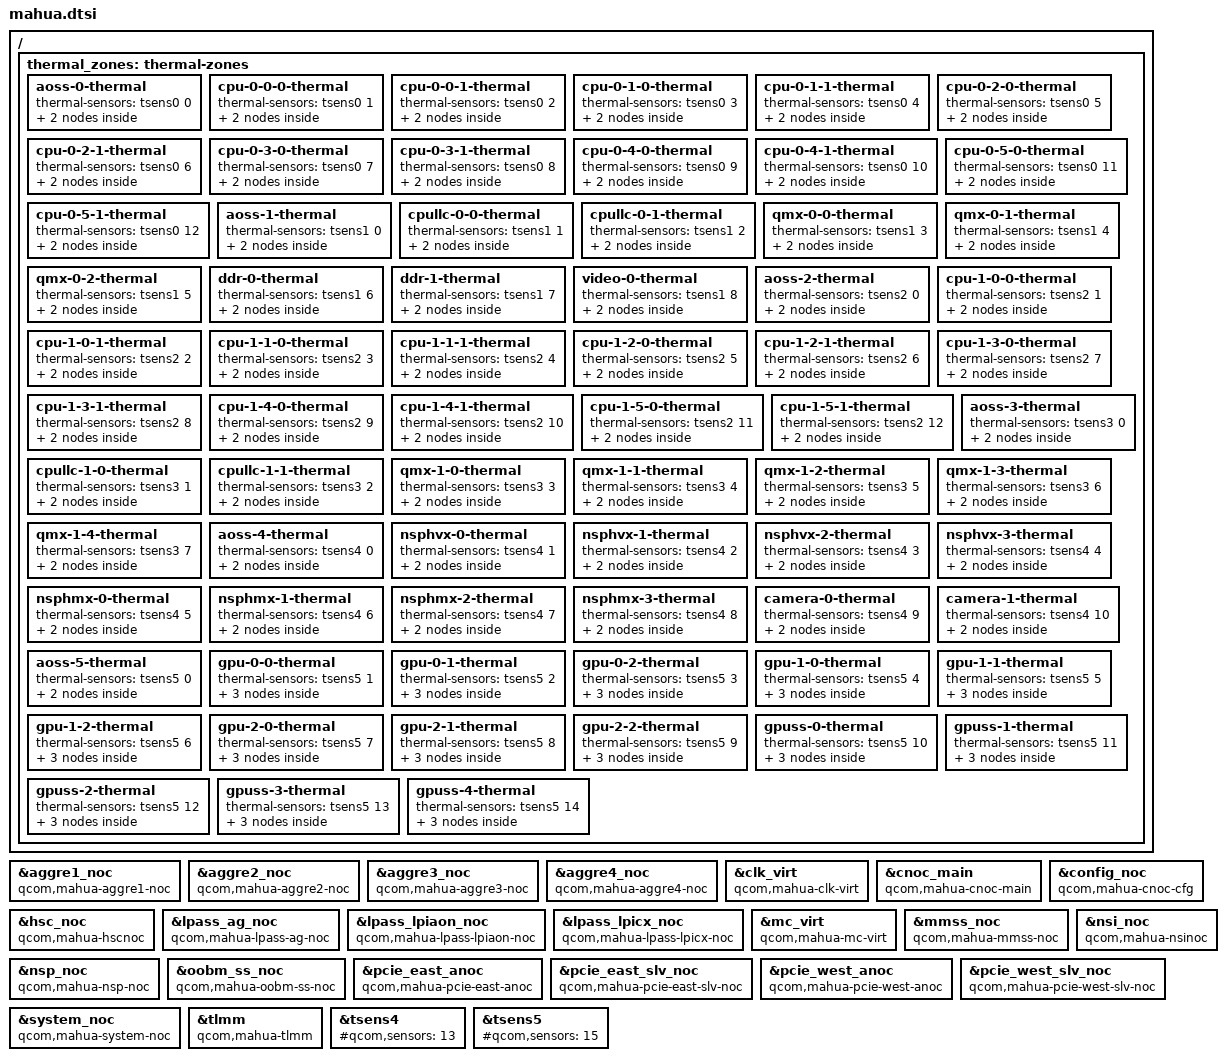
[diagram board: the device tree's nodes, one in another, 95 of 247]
// SPDX-License-Identifier: BSD-3-Clause
/*
 * Copyright (c) Qualcomm Technologies, Inc. and/or its subsidiaries.
 */

/* Mahua is heavily based on Glymur, with some meaningful differences */
#include "glymur.dtsi"

/delete-node/ &cluster2_pd;
/delete-node/ &cpu_map_cluster2;
/delete-node/ &cpu12;
/delete-node/ &cpu13;
/delete-node/ &cpu14;
/delete-node/ &cpu15;
/delete-node/ &cpu16;
/delete-node/ &cpu17;
/delete-node/ &cpu_pd12;
/delete-node/ &cpu_pd13;
/delete-node/ &cpu_pd14;
/delete-node/ &cpu_pd15;
/delete-node/ &cpu_pd16;
/delete-node/ &cpu_pd17;
/delete-node/ &thermal_zones;
/delete-node/ &tsens6;
/delete-node/ &tsens7;

&aggre1_noc {
	compatible = "qcom,mahua-aggre1-noc", "qcom,glymur-aggre1-noc";
};

&aggre2_noc {
	compatible = "qcom,mahua-aggre2-noc", "qcom,glymur-aggre2-noc";
};

&aggre3_noc {
	compatible = "qcom,mahua-aggre3-noc", "qcom,glymur-aggre3-noc";
};

&aggre4_noc {
	compatible = "qcom,mahua-aggre4-noc", "qcom,glymur-aggre4-noc";
};

&clk_virt {
	compatible = "qcom,mahua-clk-virt", "qcom,glymur-clk-virt";
};

&cnoc_main {
	compatible = "qcom,mahua-cnoc-main", "qcom,glymur-cnoc-main";
};

&config_noc {
	compatible = "qcom,mahua-cnoc-cfg";
};

&hsc_noc {
	compatible = "qcom,mahua-hscnoc";
};

&lpass_ag_noc {
	compatible = "qcom,mahua-lpass-ag-noc", "qcom,glymur-lpass-ag-noc";
};

&lpass_lpiaon_noc {
	compatible = "qcom,mahua-lpass-lpiaon-noc", "qcom,glymur-lpass-lpiaon-noc";
};

&lpass_lpicx_noc {
	compatible = "qcom,mahua-lpass-lpicx-noc", "qcom,glymur-lpass-lpicx-noc";
};

&mc_virt {
	compatible = "qcom,mahua-mc-virt";
};

&mmss_noc {
	compatible = "qcom,mahua-mmss-noc", "qcom,glymur-mmss-noc";
};

&nsi_noc {
	compatible = "qcom,mahua-nsinoc", "qcom,glymur-nsinoc";
};

&nsp_noc {
	compatible = "qcom,mahua-nsp-noc", "qcom,glymur-nsp-noc";
};

&oobm_ss_noc {
	compatible = "qcom,mahua-oobm-ss-noc", "qcom,glymur-oobm-ss-noc";
};

&pcie_east_anoc {
	compatible = "qcom,mahua-pcie-east-anoc", "qcom,glymur-pcie-east-anoc";
};

&pcie_east_slv_noc {
	compatible = "qcom,mahua-pcie-east-slv-noc", "qcom,glymur-pcie-east-slv-noc";
};

&pcie_west_anoc {
	compatible = "qcom,mahua-pcie-west-anoc";
	clocks = <&gcc GCC_AGGRE_NOC_PCIE_3B_WEST_SF_AXI_CLK>,
		 <&gcc GCC_AGGRE_NOC_PCIE_4_WEST_SF_AXI_CLK>,
		 <&gcc GCC_AGGRE_NOC_PCIE_6_WEST_SF_AXI_CLK>;
};

&pcie_west_slv_noc {
	compatible = "qcom,mahua-pcie-west-slv-noc";
};

&system_noc {
	compatible = "qcom,mahua-system-noc", "qcom,glymur-system-noc";
};

&tlmm {
	compatible = "qcom,mahua-tlmm";
};

&tsens4 {
	#qcom,sensors = <13>;
};

&tsens5 {
	#qcom,sensors = <15>;
};

/ {
	thermal_zones: thermal-zones {
		aoss-0-thermal {
			thermal-sensors = <&tsens0 0>;

			trips {
				aoss-0-critical {
					temperature = <115000>;
					hysteresis = <1000>;
					type = "critical";
				};
			};
		};

		cpu-0-0-0-thermal {
			thermal-sensors = <&tsens0 1>;

			trips {
				cpu-0-0-0-critical {
					temperature = <115000>;
					hysteresis = <1000>;
					type = "critical";
				};
			};
		};

		cpu-0-0-1-thermal {
			thermal-sensors = <&tsens0 2>;

			trips {
				cpu-0-0-1-critical {
					temperature = <115000>;
					hysteresis = <1000>;
					type = "critical";
				};
			};
		};

		cpu-0-1-0-thermal {
			thermal-sensors = <&tsens0 3>;

			trips {
				cpu-0-1-0-critical {
					temperature = <115000>;
					hysteresis = <1000>;
					type = "critical";
				};
			};
		};

		cpu-0-1-1-thermal {
			thermal-sensors = <&tsens0 4>;

			trips {
				cpu-0-1-1-critical {
					temperature = <115000>;
					hysteresis = <1000>;
					type = "critical";
				};
			};
		};

		cpu-0-2-0-thermal {
			thermal-sensors = <&tsens0 5>;

			trips {
				cpu-0-2-0-critical {
					temperature = <115000>;
					hysteresis = <1000>;
					type = "critical";
				};
			};
		};

		cpu-0-2-1-thermal {
			thermal-sensors = <&tsens0 6>;

			trips {
				cpu-0-2-1-critical {
					temperature = <115000>;
					hysteresis = <1000>;
					type = "critical";
				};
			};
		};

		cpu-0-3-0-thermal {
			thermal-sensors = <&tsens0 7>;

			trips {
				cpu-0-3-0-critical {
					temperature = <115000>;
					hysteresis = <1000>;
					type = "critical";
				};
			};
		};

		cpu-0-3-1-thermal {
			thermal-sensors = <&tsens0 8>;

			trips {
				cpu-0-3-1-critical {
					temperature = <115000>;
					hysteresis = <1000>;
					type = "critical";
				};
			};
		};

		cpu-0-4-0-thermal {
			thermal-sensors = <&tsens0 9>;

			trips {
				cpu-0-4-0-critical {
					temperature = <115000>;
					hysteresis = <1000>;
					type = "critical";
				};
			};
		};

		cpu-0-4-1-thermal {
			thermal-sensors = <&tsens0 10>;

			trips {
				cpu-0-4-1-critical {
					temperature = <115000>;
					hysteresis = <1000>;
					type = "critical";
				};
			};
		};

		cpu-0-5-0-thermal {
			thermal-sensors = <&tsens0 11>;

			trips {
				cpu-0-5-0-critical {
					temperature = <115000>;
					hysteresis = <1000>;
					type = "critical";
				};
			};
		};

		cpu-0-5-1-thermal {
			thermal-sensors = <&tsens0 12>;

			trips {
				cpu-0-5-1-critical {
					temperature = <115000>;
					hysteresis = <1000>;
					type = "critical";
				};
			};
		};

		aoss-1-thermal {
			thermal-sensors = <&tsens1 0>;

			trips {
				aoss-1-critical {
					temperature = <115000>;
					hysteresis = <1000>;
					type = "critical";
				};
			};
		};

		cpullc-0-0-thermal {
			thermal-sensors = <&tsens1 1>;

			trips {
				cpullc-0-0-critical {
					temperature = <115000>;
					hysteresis = <1000>;
					type = "critical";
				};
			};
		};

		cpullc-0-1-thermal {
			thermal-sensors = <&tsens1 2>;

			trips {
				cpullc-0-1-critical {
					temperature = <115000>;
					hysteresis = <1000>;
					type = "critical";
				};
			};
		};

		qmx-0-0-thermal {
			thermal-sensors = <&tsens1 3>;

			trips {
				qmx-0-0-critical {
					temperature = <115000>;
					hysteresis = <1000>;
					type = "critical";
				};
			};
		};

		qmx-0-1-thermal {
			thermal-sensors = <&tsens1 4>;

			trips {
				qmx-0-1-critical {
					temperature = <115000>;
					hysteresis = <1000>;
					type = "critical";
				};
			};
		};

		qmx-0-2-thermal {
			thermal-sensors = <&tsens1 5>;

			trips {
				qmx-0-2-critical {
					temperature = <115000>;
					hysteresis = <1000>;
					type = "critical";
				};
			};
		};

		ddr-0-thermal {
			thermal-sensors = <&tsens1 6>;

			trips {
				ddr-0-critical {
					temperature = <115000>;
					hysteresis = <1000>;
					type = "critical";
				};
			};
		};

		ddr-1-thermal {
			thermal-sensors = <&tsens1 7>;

			trips {
				ddr-1-critical {
					temperature = <115000>;
					hysteresis = <1000>;
					type = "critical";
				};
			};
		};

		video-0-thermal {
			thermal-sensors = <&tsens1 8>;

			trips {
				video-0-critical {
					temperature = <115000>;
					hysteresis = <1000>;
					type = "critical";
				};
			};
		};

		aoss-2-thermal {
			thermal-sensors = <&tsens2 0>;

			trips {
				aoss-2-critical {
					temperature = <115000>;
					hysteresis = <1000>;
					type = "critical";
				};
			};
		};

		cpu-1-0-0-thermal {
			thermal-sensors = <&tsens2 1>;

			trips {
				cpu-1-0-0-critical {
					temperature = <115000>;
					hysteresis = <1000>;
					type = "critical";
				};
			};
		};

		cpu-1-0-1-thermal {
			thermal-sensors = <&tsens2 2>;

			trips {
				cpu-1-0-1-critical {
					temperature = <115000>;
					hysteresis = <1000>;
					type = "critical";
				};
			};
		};

		cpu-1-1-0-thermal {
			thermal-sensors = <&tsens2 3>;

			trips {
				cpu-1-1-0-critical {
					temperature = <115000>;
					hysteresis = <1000>;
					type = "critical";
				};
			};
		};

		cpu-1-1-1-thermal {
			thermal-sensors = <&tsens2 4>;

			trips {
				cpu-1-1-1-critical {
					temperature = <115000>;
					hysteresis = <1000>;
					type = "critical";
				};
			};
		};

		cpu-1-2-0-thermal {
			thermal-sensors = <&tsens2 5>;

			trips {
				cpu-1-2-0-critical {
					temperature = <115000>;
					hysteresis = <1000>;
					type = "critical";
				};
			};
		};

		cpu-1-2-1-thermal {
			thermal-sensors = <&tsens2 6>;

			trips {
				cpu-1-2-1-critical {
					temperature = <115000>;
					hysteresis = <1000>;
					type = "critical";
				};
			};
		};

		cpu-1-3-0-thermal {
			thermal-sensors = <&tsens2 7>;

			trips {
				cpu-1-3-0-critical {
					temperature = <115000>;
					hysteresis = <1000>;
					type = "critical";
				};
			};
		};

		cpu-1-3-1-thermal {
			thermal-sensors = <&tsens2 8>;

			trips {
				cpu-1-3-1-critical {
					temperature = <115000>;
					hysteresis = <1000>;
					type = "critical";
				};
			};
		};

		cpu-1-4-0-thermal {
			thermal-sensors = <&tsens2 9>;

			trips {
				cpu-1-4-0-critical {
					temperature = <115000>;
					hysteresis = <1000>;
					type = "critical";
				};
			};
		};

		cpu-1-4-1-thermal {
			thermal-sensors = <&tsens2 10>;

			trips {
				cpu-1-4-1-critical {
					temperature = <115000>;
					hysteresis = <1000>;
					type = "critical";
				};
			};
		};

		cpu-1-5-0-thermal {
			thermal-sensors = <&tsens2 11>;

			trips {
				cpu-1-5-0-critical {
					temperature = <115000>;
					hysteresis = <1000>;
					type = "critical";
				};
			};
		};

		cpu-1-5-1-thermal {
			thermal-sensors = <&tsens2 12>;

			trips {
				cpu-1-5-1-critical {
					temperature = <115000>;
					hysteresis = <1000>;
					type = "critical";
				};
			};
		};

		aoss-3-thermal {
			thermal-sensors = <&tsens3 0>;

			trips {
				aoss-3-critical {
					temperature = <115000>;
					hysteresis = <1000>;
					type = "critical";
				};
			};
		};

		cpullc-1-0-thermal {
			thermal-sensors = <&tsens3 1>;

			trips {
				cpullc-1-0-critical {
					temperature = <115000>;
					hysteresis = <1000>;
					type = "critical";
				};
			};
		};

		cpullc-1-1-thermal {
			thermal-sensors = <&tsens3 2>;

			trips {
				cpullc-1-1-critical {
					temperature = <115000>;
					hysteresis = <1000>;
					type = "critical";
				};
			};
		};

		qmx-1-0-thermal {
			thermal-sensors = <&tsens3 3>;

			trips {
				qmx-1-0-critical {
					temperature = <115000>;
					hysteresis = <1000>;
					type = "critical";
				};
			};
		};

		qmx-1-1-thermal {
			thermal-sensors = <&tsens3 4>;

			trips {
				qmx-1-1-critical {
					temperature = <115000>;
					hysteresis = <1000>;
					type = "critical";
				};
			};
		};

		qmx-1-2-thermal {
			thermal-sensors = <&tsens3 5>;

			trips {
				qmx-1-2-critical {
					temperature = <115000>;
					hysteresis = <1000>;
					type = "critical";
				};
			};
		};

		qmx-1-3-thermal {
			thermal-sensors = <&tsens3 6>;

			trips {
				qmx-1-3-critical {
					temperature = <115000>;
					hysteresis = <1000>;
					type = "critical";
				};
			};
		};

		qmx-1-4-thermal {
			thermal-sensors = <&tsens3 7>;

			trips {
				qmx-1-4-critical {
					temperature = <115000>;
					hysteresis = <1000>;
					type = "critical";
				};
			};
		};

		aoss-4-thermal {
			thermal-sensors = <&tsens4 0>;

			trips {
				aoss-4-critical {
					temperature = <115000>;
					hysteresis = <1000>;
					type = "critical";
				};
			};
		};

		nsphvx-0-thermal {
			thermal-sensors = <&tsens4 1>;

			trips {
				nsphvx-0-critical {
					temperature = <115000>;
					hysteresis = <1000>;
					type = "critical";
				};
			};
		};

		nsphvx-1-thermal {
			thermal-sensors = <&tsens4 2>;

			trips {
				nsphvx-1-critical {
					temperature = <115000>;
					hysteresis = <1000>;
					type = "critical";
				};
			};
		};

		nsphvx-2-thermal {
			thermal-sensors = <&tsens4 3>;

			trips {
				nsphvx-2-critical {
					temperature = <115000>;
					hysteresis = <1000>;
					type = "critical";
				};
			};
		};

		nsphvx-3-thermal {
			thermal-sensors = <&tsens4 4>;

			trips {
				nsphvx-3-critical {
					temperature = <115000>;
					hysteresis = <1000>;
					type = "critical";
				};
			};
		};

		nsphmx-0-thermal {
			thermal-sensors = <&tsens4 5>;

			trips {
				nsphmx-0-critical {
					temperature = <115000>;
					hysteresis = <1000>;
					type = "critical";
				};
			};
		};

		nsphmx-1-thermal {
			thermal-sensors = <&tsens4 6>;

			trips {
				nsphmx-1-critical {
					temperature = <115000>;
					hysteresis = <1000>;
					type = "critical";
				};
			};
		};

		nsphmx-2-thermal {
			thermal-sensors = <&tsens4 7>;

			trips {
				nsphmx-2-critical {
					temperature = <115000>;
					hysteresis = <1000>;
					type = "critical";
				};
			};
		};

		nsphmx-3-thermal {
			thermal-sensors = <&tsens4 8>;

			trips {
				nsphmx-3-critical {
					temperature = <115000>;
					hysteresis = <1000>;
					type = "critical";
				};
			};
		};

		camera-0-thermal {
			thermal-sensors = <&tsens4 9>;

			trips {
				camera-0-critical {
					temperature = <115000>;
					hysteresis = <1000>;
					type = "critical";
				};
			};
		};

		camera-1-thermal {
			thermal-sensors = <&tsens4 10>;

			trips {
				camera-1-critical {
					temperature = <115000>;
					hysteresis = <1000>;
					type = "critical";
				};
			};
		};

		aoss-5-thermal {
			thermal-sensors = <&tsens5 0>;

			trips {
				aoss-5-critical {
					temperature = <115000>;
					hysteresis = <1000>;
					type = "critical";
				};
			};
		};

		gpu-0-0-thermal {
			thermal-sensors = <&tsens5 1>;

			trips {
				trip-point0 {
					temperature = <90000>;
					hysteresis = <5000>;
					type = "hot";
				};

				gpu-0-0-critical {
					temperature = <115000>;
					hysteresis = <1000>;
					type = "critical";
				};
			};
		};

		gpu-0-1-thermal {
			thermal-sensors = <&tsens5 2>;

			trips {
				trip-point0 {
					temperature = <90000>;
					hysteresis = <5000>;
					type = "hot";
				};

				gpu-0-1-critical {
					temperature = <115000>;
					hysteresis = <1000>;
					type = "critical";
				};
			};
		};

		gpu-0-2-thermal {
			thermal-sensors = <&tsens5 3>;

			trips {
				trip-point0 {
					temperature = <90000>;
					hysteresis = <5000>;
					type = "hot";
				};

				gpu-0-2-critical {
					temperature = <115000>;
					hysteresis = <1000>;
					type = "critical";
				};
			};
		};

		gpu-1-0-thermal {
			thermal-sensors = <&tsens5 4>;

			trips {
				trip-point0 {
					temperature = <90000>;
					hysteresis = <5000>;
					type = "hot";
				};

				gpu-1-0-critical {
					temperature = <115000>;
					hysteresis = <1000>;
					type = "critical";
				};
			};
		};

		gpu-1-1-thermal {
			thermal-sensors = <&tsens5 5>;

			trips {
				trip-point0 {
					temperature = <90000>;
					hysteresis = <5000>;
					type = "hot";
				};

				gpu-1-1-critical {
					temperature = <115000>;
					hysteresis = <1000>;
					type = "critical";
				};
			};
		};

		gpu-1-2-thermal {
			thermal-sensors = <&tsens5 6>;

			trips {
				trip-point0 {
					temperature = <90000>;
					hysteresis = <5000>;
					type = "hot";
				};

				gpu-1-2-critical {
					temperature = <115000>;
					hysteresis = <1000>;
					type = "critical";
				};
			};
		};

		gpu-2-0-thermal {
			thermal-sensors = <&tsens5 7>;

			trips {
				trip-point0 {
					temperature = <90000>;
					hysteresis = <5000>;
					type = "hot";
				};

				gpu-2-0-critical {
					temperature = <115000>;
					hysteresis = <1000>;
					type = "critical";
				};
			};
		};

		gpu-2-1-thermal {
			thermal-sensors = <&tsens5 8>;

			trips {
				trip-point0 {
					temperature = <90000>;
					hysteresis = <5000>;
					type = "hot";
				};

				gpu-2-1-critical {
					temperature = <115000>;
					hysteresis = <1000>;
					type = "critical";
				};
			};
		};

		gpu-2-2-thermal {
			thermal-sensors = <&tsens5 9>;

			trips {
				trip-point0 {
					temperature = <90000>;
					hysteresis = <5000>;
					type = "hot";
				};

				gpu-2-2-critical {
					temperature = <115000>;
					hysteresis = <1000>;
					type = "critical";
				};
			};
		};

		gpuss-0-thermal {
			thermal-sensors = <&tsens5 10>;

			trips {
				trip-point0 {
					temperature = <90000>;
					hysteresis = <5000>;
					type = "hot";
				};

				gpuss-0-critical {
					temperature = <115000>;
					hysteresis = <1000>;
					type = "critical";
				};
			};
		};

		gpuss-1-thermal {
			thermal-sensors = <&tsens5 11>;

			trips {
				trip-point0 {
					temperature = <90000>;
					hysteresis = <5000>;
					type = "hot";
				};

				gpuss-1-critical {
					temperature = <115000>;
					hysteresis = <1000>;
					type = "critical";
				};
			};
		};

		gpuss-2-thermal {
			thermal-sensors = <&tsens5 12>;

			trips {
				trip-point0 {
					temperature = <90000>;
					hysteresis = <5000>;
					type = "hot";
				};

				gpuss-2-critical {
					temperature = <115000>;
					hysteresis = <1000>;
					type = "critical";
				};
			};
		};

		gpuss-3-thermal {
			thermal-sensors = <&tsens5 13>;

			trips {
				trip-point0 {
					temperature = <90000>;
					hysteresis = <5000>;
					type = "hot";
				};

				gpuss-3-critical {
					temperature = <115000>;
					hysteresis = <1000>;
					type = "critical";
				};
			};
		};

		gpuss-4-thermal {
			thermal-sensors = <&tsens5 14>;

			trips {
				trip-point0 {
					temperature = <90000>;
					hysteresis = <5000>;
					type = "hot";
				};

				gpuss-4-critical {
					temperature = <115000>;
					hysteresis = <1000>;
					type = "critical";
				};
			};
		};
	};
};
